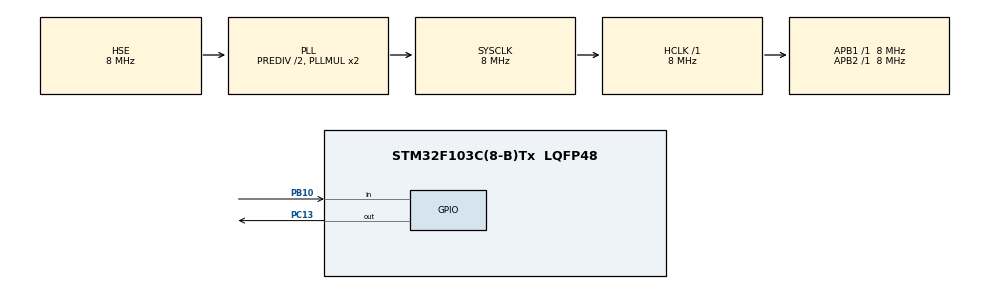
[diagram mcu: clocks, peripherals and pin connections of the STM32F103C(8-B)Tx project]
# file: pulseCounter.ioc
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Mcu.Family=STM32F1
RCC.PLLSourceVirtual=RCC_PLLSOURCE_HSE
PD1-OSC_OUT.Mode=HSE-External-Oscillator
PC13-TAMPER-RTC.Signal=GPIO_Output
PD0-OSC_IN.Signal=RCC_OSC_IN
RCC.SYSCLKSource=RCC_SYSCLKSOURCE_PLLCLK
ProjectManager.StackSize=0x400
PD1-OSC_OUT.Signal=RCC_OSC_OUT
PA13.Signal=SYS_JTMS-SWDIO
ProjectManager.TargetToolchain=STM32CubeIDE
RCC.HCLKFreq_Value=8000000
RCC.APB2TimFreq_Value=8000000
RCC.USBFreq_Value=8000000
RCC.AHBFreq_Value=8000000
PD0-OSC_IN.Mode=HSE-External-Oscillator
PB10.Signal=GPIO_Input
board=custom
RCC.APB2Freq_Value=8000000
PA14.Mode=Serial_Wire
PA13.Mode=Serial_Wire
Mcu.Name=STM32F103C(8-B)Tx
RCC.SYSCLKFreq_VALUE=8000000
Mcu.Package=LQFP48
RCC.HSEDivPLL=RCC_HSE_PREDIV_DIV2
PA14.Signal=SYS_JTCK-SWCLK
ProjectManager.HeapSize=0x200
NVIC.PriorityGroup=NVIC_PRIORITYGROUP_4
RCC.APB1TimFreq_Value=8000000
RCC.APB1Freq_Value=8000000

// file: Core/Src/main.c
/* USER CODE BEGIN Header */
/**
 ******************************************************************************
 * @file           : main.c
 * @brief          : Main program body
 ******************************************************************************
 * @attention
 *
 * <h2><center>&copy; Copyright (c) 2022 STMicroelectronics.
 * All rights reserved.</center></h2>
 *
 * This software component is licensed by ST under BSD 3-Clause license,
 * the "License"; You may not use this file except in compliance with the
 * License. You may obtain a copy of the License at:
 *                        opensource.org/licenses/BSD-3-Clause
 *
 ******************************************************************************
 */
/* USER CODE END Header */
#include "main.h"

/* USER CODE BEGIN PD */
#define GPIO_NUMBER 16
/* USER CODE END PD */

void SystemClock_Config(void);
static void MX_GPIO_Init(void);
/* USER CODE BEGIN PFP */
void update_led(void);
void toggle_led(void);

/* USER CODE END PFP */

int main(void)
{

	/* MCU Configuration--------------------------------------------------------*/

	/* Reset of all peripherals, Initializes the Flash interface and the Systick. */
	HAL_Init();

	/* Configure the system clock */
	SystemClock_Config();

	/* Initialize all configured peripherals */
	MX_GPIO_Init();

	/* Infinite loop */
	while (1)
	{

		/* USER CODE BEGIN 3 */
		/*
			##1 - Toggle led with 1 second delay
		 */
//		 toggle_led();

		/*
			##2 - READING A DIGITAL VALUE
		 */
		 update_led();
	}
	/* USER CODE END 3 */
}

void SystemClock_Config(void)
{
	RCC_OscInitTypeDef RCC_OscInitStruct = {0};
	RCC_ClkInitTypeDef RCC_ClkInitStruct = {0};

	/** Initializes the RCC Oscillators according to the specified parameters
	 * in the RCC_OscInitTypeDef structure.
	 */
	RCC_OscInitStruct.OscillatorType = RCC_OSCILLATORTYPE_HSE;
	RCC_OscInitStruct.HSEState = RCC_HSE_ON;
	RCC_OscInitStruct.HSEPredivValue = RCC_HSE_PREDIV_DIV2;
	RCC_OscInitStruct.HSIState = RCC_HSI_ON;
	RCC_OscInitStruct.PLL.PLLState = RCC_PLL_ON;
	RCC_OscInitStruct.PLL.PLLSource = RCC_PLLSOURCE_HSE;
	RCC_OscInitStruct.PLL.PLLMUL = RCC_PLL_MUL2;
	if (HAL_RCC_OscConfig(&RCC_OscInitStruct) != HAL_OK)
	{
		Error_Handler();
	}
	/** Initializes the CPU, AHB and APB buses clocks
	 */
	RCC_ClkInitStruct.ClockType = RCC_CLOCKTYPE_HCLK|RCC_CLOCKTYPE_SYSCLK
			|RCC_CLOCKTYPE_PCLK1|RCC_CLOCKTYPE_PCLK2;
	RCC_ClkInitStruct.SYSCLKSource = RCC_SYSCLKSOURCE_PLLCLK;
	RCC_ClkInitStruct.AHBCLKDivider = RCC_SYSCLK_DIV1;
	RCC_ClkInitStruct.APB1CLKDivider = RCC_HCLK_DIV1;
	RCC_ClkInitStruct.APB2CLKDivider = RCC_HCLK_DIV1;

	if (HAL_RCC_ClockConfig(&RCC_ClkInitStruct, FLASH_LATENCY_0) != HAL_OK)
	{
		Error_Handler();
	}
}

static void MX_GPIO_Init(void)
{
	GPIO_InitTypeDef GPIO_InitStruct = {0};

	/* GPIO Ports Clock Enable */
	__HAL_RCC_GPIOC_CLK_ENABLE();
	__HAL_RCC_GPIOD_CLK_ENABLE();
	__HAL_RCC_GPIOB_CLK_ENABLE();
	__HAL_RCC_GPIOA_CLK_ENABLE();

	/*Configure GPIO pin Output Level */
	HAL_GPIO_WritePin(GPIOC, GPIO_PIN_13, GPIO_PIN_RESET);

	/*Configure GPIO pin : PC13 */
	GPIO_InitStruct.Pin = GPIO_PIN_13;
	GPIO_InitStruct.Mode = GPIO_MODE_OUTPUT_PP;
	GPIO_InitStruct.Pull = GPIO_NOPULL;
	GPIO_InitStruct.Speed = GPIO_SPEED_FREQ_LOW;
	HAL_GPIO_Init(GPIOC, &GPIO_InitStruct);

	/*Configure GPIO pin : PB10 */
	GPIO_InitStruct.Pin = GPIO_PIN_10;
	GPIO_InitStruct.Mode = GPIO_MODE_INPUT;
	GPIO_InitStruct.Pull = GPIO_NOPULL;
	HAL_GPIO_Init(GPIOB, &GPIO_InitStruct);

}

/* USER CODE BEGIN 4 */
/*
 * 	Here we power on the led when the button is pressed and turn off when it's not.
 * 	This function contains a 50ms delay as a simple and enough solution for debounce.
 * 	NOTE: HAL_GPIO_ReadPin is active-low
 */
void update_led(void){

//	!HAL_GPIO_ReadPin(GPIOB, GPIO_PIN_10) ? (GPIOC->ODR |= GPIO_PIN_13) : (GPIOC->ODR &= ~GPIO_PIN_13);
	GPIOB->IDR & GPIO_PIN_10  ? (GPIOC->ODR &= ~GPIO_PIN_13) : (GPIOC->ODR |= GPIO_PIN_13);
	HAL_Delay(50);
}

/* BLINKING LEDS
 * 	Here we toggle the built-in led each 1 sec
 */
void toggle_led(void){
	// Using HAL
	// HAL_GPIO_TogglePin(GPIOC, GPIO_PIN_13);
	/* ------------- */

	// Using ODR
	GPIOC->ODR^=GPIO_PIN_13;
	/* ------------- */

	// Using BSRR (used by hal)
	// uint32_t shift_number = (GPIO_NUMBER * ((GPIOC->ODR & GPIO_PIN_13) > 0));
	// GPIOC->BSRR = (uint32_t)(GPIO_PIN_13 << shift_number);
	// GPIOC->BSRR = (GPIOC->ODR & GPIO_PIN_13) > 0 ? GPIO_PIN_13 << 16 : GPIO_PIN_13;
	/* ------------- */
	HAL_Delay(1000);
}
/* USER CODE END 4 */

void Error_Handler(void)
{
	__disable_irq();
	while (1)
	{
	}
}

/************************ (C) COPYRIGHT STMicroelectronics *****END OF FILE****/
